# CY8C4248AZI_L485 register map
File version: 0.1
PSoC 4200L
Registers are 32-bit, read-write, no defined reset value unless marked. A register's access mark holds for its fields unless they carry their own. Offsets are from the block's base; lines under a group give offsets from that group; [hi:lo] are bit positions; {n}, {i} and the like mark numbered series; 'fields as' and 'values as' point back to an identical list; <NAME> marks a mode.

## Memory map
0x00000000 Can_addr
0x00000000 QuadDec_1
0x00000000 UART — Serial Communication Block
0x00000000 QuadDec_2
0x00000000 Timer_1ms
0x00000000 DMAC — DMAC Registers
0x00000000 Timer_LEDs
0x00000000 Status_Reg_LIM
0x00000000 ADC — Sequencing SAR ADC
0x00000000 CAN
0x00000000 I2C — Serial Communication Block

## Can_addr
Base 0x00000000
0x400F0063 Can_addr_STATUS_REG 8-bit
0x400F0083 Can_addr_MASK_REG 8-bit
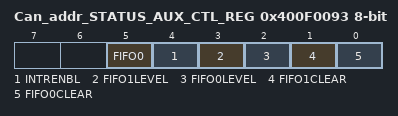
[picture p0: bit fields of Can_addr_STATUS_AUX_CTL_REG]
0x400F0093 Can_addr_STATUS_AUX_CTL_REG 8-bit
  [5] FIFO0 — FIFO0 clear
    1=ENABLED (Enable counter); 0=DISABLED (Disable counter)
  [4] INTRENBL — Enables or disables the Interrupt
    1=ENABLED (Interrupt enabled); 0=DISABLED (Interrupt disabled)
  [3] FIFO1LEVEL — FIFO level
    1=ENABLED (FIFO LVL: input mode: FIFO at least 1/2 empty; output mode: FIFO at least 1/2 full); 0=DISABLED (FIFO LVL: input mode: FIFO not full; output mode: FIFO not empty)
  [2] FIFO0LEVEL — FIFO level
    values as FIFO1LEVEL
  [1] FIFO1CLEAR — FIFO clear
    1=ENABLED (Clear FIFO state); 0=DISABLED (Normal FIFO operation)
  [0] FIFO0CLEAR — FIFO clear
    values as FIFO1CLEAR

## QuadDec_1
Base 0x00000000
0x40200108 COUNTER — Current counter value
0x4020010C CC — Compare / capture value
0x40200110 CC_BUF — Compare / capture buffer value
0x40200114 PERIOD — Period value
0x40200118 PERIOD_BUF — Period buffer value

## QuadDec_2
Base 0x00000000
0x40200148 COUNTER — Current counter value
0x4020014C CC — Compare / capture value
0x40200150 CC_BUF — Compare / capture buffer value
0x40200154 PERIOD — Period value
0x40200158 PERIOD_BUF — Period buffer value

## Timer_1ms
Base 0x00000000
0x400F0006 Timer_1ms_COUNTER 16-bit — UDB.A0 - Current Down Counter Value
0x400F0026 Timer_1ms_PERIOD 16-bit — UDB.D0 - Assigned Period
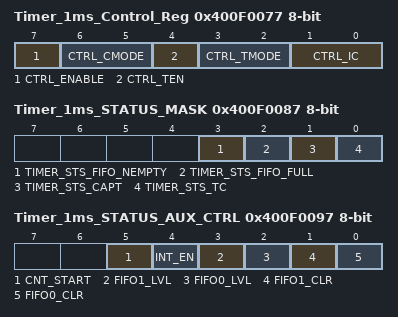
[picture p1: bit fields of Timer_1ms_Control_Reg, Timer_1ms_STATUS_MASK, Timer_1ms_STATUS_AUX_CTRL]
0x400F0077 Timer_1ms_Control_Reg 8-bit — UDB Control Register - Assigned Control Register Value
  [7] CTRL_ENABLE — Enable the Timer
  [6:5] CTRL_CMODE — Capture Mode
  [4] CTRL_TEN — Trigger Enable Bit
  [3:2] CTRL_TMODE — Trigger Mode
  [1:0] CTRL_IC — Interrupt Count
0x400F0087 Timer_1ms_STATUS_MASK 8-bit — UDB Status bits Interrupt Mask Enable Register
  [3] TIMER_STS_FIFO_NEMPTY ro — FIFO Empty status
  [2] TIMER_STS_FIFO_FULL ro — FIFO Full Status
  [1] TIMER_STS_CAPT ro — Enables the Interrupt on Capture
  [0] TIMER_STS_TC ro — Enables the Interrupt on TC
0x400F0097 Timer_1ms_STATUS_AUX_CTRL 8-bit — UDB Auxilliary Control Register
  [5] CNT_START — FIFO0 clear
    0=E_CNT_START0 (Disable counter); 1=E_CNT_START1 (Enable counter)
  [4] INT_EN
    0=E_INT_EN0 (Interrupt disabled); 1=E_INT_EN1 (Interrupt enabled)
  [3] FIFO1_LVL — FIFO level
    0=E_FIFO_LVL_0 (FIFO LVL: input mode: FIFO not full; output mode: FIFO not empty); 1=E_FIFO_LVL_1 (FIFO LVL: input mode: FIFO at least 1/2 empty; output mode: FIFO at least 1/2 full)
  [2] FIFO0_LVL — FIFO level
    values as FIFO1_LVL
  [1] FIFO1_CLR — FIFO1 clear
    0=E_FIFO_CLR_0 (Normal FIFO operation); 1=E_FIFO_CLR_1 (Clear FIFO state)
  [0] FIFO0_CLR — FIFO0 clear
    values as FIFO1_CLR

## Timer_LEDs
Base 0x00000000
0x400F0002 Timer_LEDs_COUNTER 24-bit — UDB.A0 - Current Down Counter Value
0x400F0022 Timer_LEDs_PERIOD 24-bit — UDB.D0 - Assigned Period
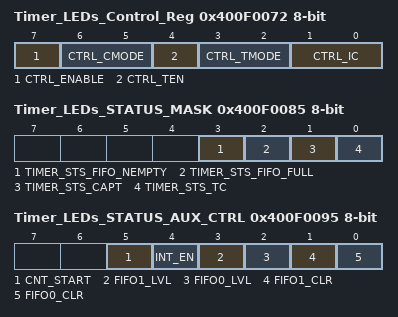
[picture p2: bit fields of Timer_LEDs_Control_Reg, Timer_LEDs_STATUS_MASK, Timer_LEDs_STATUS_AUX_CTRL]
0x400F0072 Timer_LEDs_Control_Reg 8-bit — UDB Control Register - Assigned Control Register Value
  [7] CTRL_ENABLE — Enable the Timer
  [6:5] CTRL_CMODE — Capture Mode
  [4] CTRL_TEN — Trigger Enable Bit
  [3:2] CTRL_TMODE — Trigger Mode
  [1:0] CTRL_IC — Interrupt Count
0x400F0085 Timer_LEDs_STATUS_MASK 8-bit — UDB Status bits Interrupt Mask Enable Register
  [3] TIMER_STS_FIFO_NEMPTY ro — FIFO Empty status
  [2] TIMER_STS_FIFO_FULL ro — FIFO Full Status
  [1] TIMER_STS_CAPT ro — Enables the Interrupt on Capture
  [0] TIMER_STS_TC ro — Enables the Interrupt on TC
0x400F0095 Timer_LEDs_STATUS_AUX_CTRL 8-bit — UDB Auxilliary Control Register
  [5] CNT_START — FIFO0 clear
    0=E_CNT_START0 (Disable counter); 1=E_CNT_START1 (Enable counter)
  [4] INT_EN
    0=E_INT_EN0 (Interrupt disabled); 1=E_INT_EN1 (Interrupt enabled)
  [3] FIFO1_LVL — FIFO level
    0=E_FIFO_LVL_0 (FIFO LVL: input mode: FIFO not full; output mode: FIFO not empty); 1=E_FIFO_LVL_1 (FIFO LVL: input mode: FIFO at least 1/2 empty; output mode: FIFO at least 1/2 full)
  [2] FIFO0_LVL — FIFO level
    values as FIFO1_LVL
  [1] FIFO1_CLR — FIFO1 clear
    0=E_FIFO_CLR_0 (Normal FIFO operation); 1=E_FIFO_CLR_1 (Clear FIFO state)
  [0] FIFO0_CLR — FIFO0 clear
    values as FIFO1_CLR
